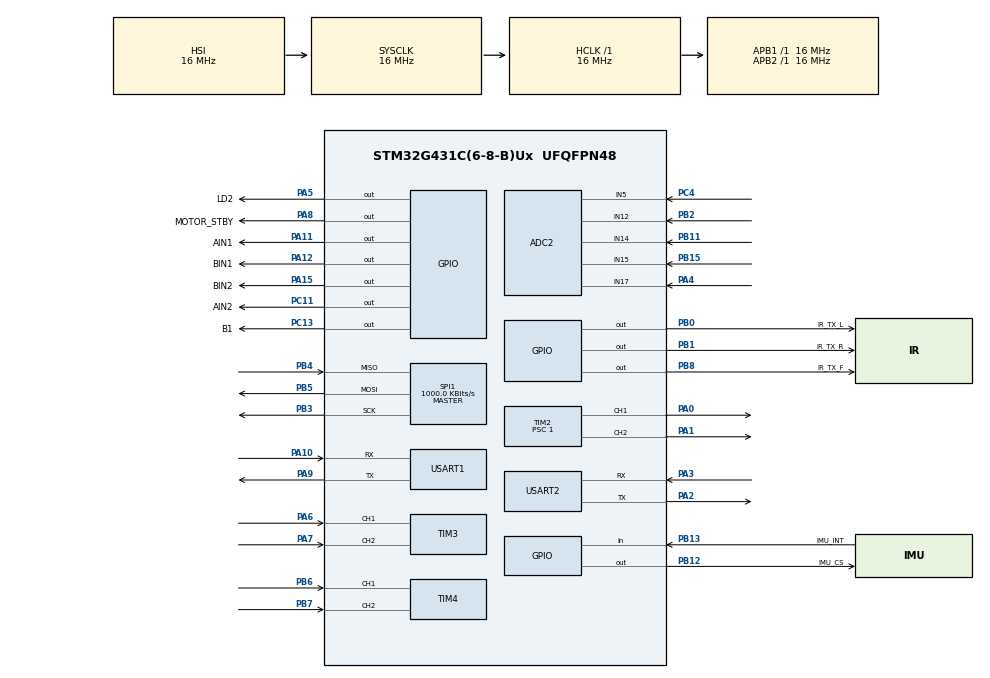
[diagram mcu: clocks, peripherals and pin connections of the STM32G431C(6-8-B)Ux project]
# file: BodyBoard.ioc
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ADC2.Channel-0\#ChannelRegularConversion=ADC_CHANNEL_5
ADC2.ClockPrescaler=ADC_CLOCK_SYNC_PCLK_DIV4
ADC2.NbrOfConversionFlag=1
ADC2.OffsetNumber-0\#ChannelRegularConversion=ADC_OFFSET_NONE
ADC2.Rank-0\#ChannelRegularConversion=1
ADC2.SamplingTime-0\#ChannelRegularConversion=ADC_SAMPLETIME_2CYCLES_5
Dma.Request0=USART1_RX
Dma.Request1=USART1_TX
Dma.USART1_RX.0.Direction=DMA_PERIPH_TO_MEMORY
Dma.USART1_RX.0.EventEnable=DISABLE
Dma.USART1_RX.0.Instance=DMA1_Channel1
Dma.USART1_RX.0.MemDataAlignment=DMA_MDATAALIGN_BYTE
Dma.USART1_RX.0.MemInc=DMA_MINC_ENABLE
Dma.USART1_RX.0.Mode=DMA_CIRCULAR
Dma.USART1_RX.0.PeriphDataAlignment=DMA_PDATAALIGN_BYTE
Dma.USART1_RX.0.PeriphInc=DMA_PINC_DISABLE
Dma.USART1_RX.0.Polarity=HAL_DMAMUX_REQ_GEN_RISING
Dma.USART1_RX.0.Priority=DMA_PRIORITY_LOW
Dma.USART1_RX.0.RequestNumber=1
Dma.USART1_RX.0.SignalID=NONE
Dma.USART1_RX.0.SyncEnable=DISABLE
Dma.USART1_RX.0.SyncPolarity=HAL_DMAMUX_SYNC_NO_EVENT
Dma.USART1_RX.0.SyncRequestNumber=1
Dma.USART1_RX.0.SyncSignalID=NONE
Dma.USART1_TX.1.Direction=DMA_MEMORY_TO_PERIPH
Dma.USART1_TX.1.EventEnable=DISABLE
Dma.USART1_TX.1.Instance=DMA1_Channel2
Dma.USART1_TX.1.MemDataAlignment=DMA_MDATAALIGN_BYTE
Dma.USART1_TX.1.MemInc=DMA_MINC_ENABLE
Dma.USART1_TX.1.Mode=DMA_NORMAL
Dma.USART1_TX.1.PeriphDataAlignment=DMA_PDATAALIGN_BYTE
Dma.USART1_TX.1.PeriphInc=DMA_PINC_DISABLE
Dma.USART1_TX.1.Polarity=HAL_DMAMUX_REQ_GEN_RISING
Dma.USART1_TX.1.Priority=DMA_PRIORITY_LOW
Dma.USART1_TX.1.RequestNumber=1
Dma.USART1_TX.1.SignalID=NONE
Dma.USART1_TX.1.SyncEnable=DISABLE
Dma.USART1_TX.1.SyncPolarity=HAL_DMAMUX_SYNC_NO_EVENT
Dma.USART1_TX.1.SyncRequestNumber=1
Dma.USART1_TX.1.SyncSignalID=NONE
Mcu.Family=STM32G4
Mcu.Name=STM32G431C(6-8-B)Ux
Mcu.Package=UFQFPN48
NVIC.DMA1_Channel1_IRQn=true\:0\:0\:false\:false\:true\:false\:true\:true
NVIC.DMA1_Channel2_IRQn=true\:0\:0\:false\:false\:true\:false\:true\:true
NVIC.PriorityGroup=NVIC_PRIORITYGROUP_4
NVIC.TIM6_DAC_IRQn=true\:0\:0\:false\:false\:true\:true\:true\:true
NVIC.USART1_IRQn=true\:0\:0\:false\:false\:true\:true\:true\:true
PA0.Signal=S_TIM2_CH1
PA1.Signal=S_TIM2_CH2
PA10.Mode=Asynchronous
PA10.Signal=USART1_RX
PA11.GPIO_Label=AIN1
PA11.Signal=GPIO_Output
PA12.GPIO_Label=BIN1
PA12.Signal=GPIO_Output
PA13.Mode=Serial_Wire
PA13.Signal=SYS_JTMS-SWDIO
PA14.Mode=Serial_Wire
PA14.Signal=SYS_JTCK-SWCLK
PA15.GPIO_Label=BIN2
PA15.Signal=GPIO_Output
PA2.Mode=Asynchronous
PA2.Signal=USART2_TX
PA3.Mode=Asynchronous
PA3.Signal=USART2_RX
PA4.Mode=IN17-Single-Ended
PA4.Signal=ADC2_IN17
PA5.GPIO_Label=LD2
PA5.Signal=GPIO_Output
PA6.Signal=S_TIM3_CH1
PA7.Signal=S_TIM3_CH2
PA8.GPIO_Label=MOTOR_STBY
PA8.PinState=GPIO_PIN_RESET
PA8.Signal=GPIO_Output
PA9.Mode=Asynchronous
PA9.Signal=USART1_TX
PB0.GPIO_Label=IR_TX_L
PB0.Signal=GPIO_Output
PB1.GPIO_Label=IR_TX_R
PB1.Signal=GPIO_Output
PB11.Mode=IN14-Single-Ended
PB11.Signal=ADC2_IN14
PB12.GPIO_Label=IMU_CS
PB12.Signal=GPIO_Output
PB13.GPIO_Label=IMU_INT
PB13.Signal=GPIO_Input
PB15.Mode=IN15-Single-Ended
PB15.Signal=ADC2_IN15
PB2.Mode=IN12-Single-Ended
PB2.Signal=ADC2_IN12
PB3.Mode=Full_Duplex_Master
PB3.Signal=SPI1_SCK
PB4.Mode=Full_Duplex_Master
PB4.Signal=SPI1_MISO
PB5.Mode=Full_Duplex_Master
PB5.Signal=SPI1_MOSI
PB6.Signal=S_TIM4_CH1
PB7.Signal=S_TIM4_CH2
PB8-BOOT0.GPIO_Label=IR_TX_F
PB8-BOOT0.Signal=GPIO_Output
PC11.GPIO_Label=AIN2
PC11.Signal=GPIO_Output
PC13.GPIO_Label=B1
PC13.Signal=GPIO_Output
PC4.Mode=IN5-Single-Ended
PC4.Signal=ADC2_IN5
PF0-OSC_IN.Mode=HSE-External-Oscillator
PF0-OSC_IN.Signal=RCC_OSC_IN
PF1-OSC_OUT.Mode=HSE-External-Oscillator
PF1-OSC_OUT.Signal=RCC_OSC_OUT
ProjectManager.HeapSize=0x200
ProjectManager.StackSize=0x400
ProjectManager.TargetToolchain=CMake
RCC.AHBFreq_Value=16000000
RCC.APB1Freq_Value=16000000
RCC.APB1TimFreq_Value=16000000
RCC.APB2Freq_Value=16000000
RCC.APB2TimFreq_Value=16000000
RCC.CortexFreq_Value=16000000
RCC.EXTERNAL_CLOCK_VALUE=12288000
RCC.HCLKFreq_Value=16000000
RCC.HSE_VALUE=8000000
RCC.HSI48_VALUE=48000000
RCC.HSI_VALUE=16000000
RCC.LSE_VALUE=32768
RCC.PLLM=RCC_PLLM_DIV2
RCC.PLLN=85
RCC.PLLSourceVirtual=RCC_PLLSOURCE_HSE
RCC.SYSCLKFreq_VALUE=16000000
RCC.USBFreq_Value=170000000
RCC.VCOOutputFreq_Value=340000000
SH.S_TIM2_CH1.0=TIM2_CH1,PWM Generation1 CH1
SH.S_TIM2_CH2.0=TIM2_CH2,PWM Generation2 CH2
SH.S_TIM3_CH1.0=TIM3_CH1,Encoder_Interface
SH.S_TIM3_CH2.0=TIM3_CH2,Encoder_Interface
SH.S_TIM4_CH1.0=TIM4_CH1,Encoder_Interface
SH.S_TIM4_CH2.0=TIM4_CH2,Encoder_Interface
SPI1.BaudRatePrescaler=SPI_BAUDRATEPRESCALER_16
SPI1.CLKPhase=SPI_PHASE_2EDGE
SPI1.CLKPolarity=SPI_POLARITY_HIGH
SPI1.CalculateBaudRate=1000.0 KBits/s
SPI1.DataSize=SPI_DATASIZE_8BIT
SPI1.Direction=SPI_DIRECTION_2LINES
SPI1.Mode=SPI_MODE_MASTER
SPI1.VirtualType=VM_MASTER
TIM2.Channel-PWM\ Generation1\ CH1=TIM_CHANNEL_1
TIM2.Channel-PWM\ Generation2\ CH2=TIM_CHANNEL_2
TIM2.PeriodNoDither=4199
TIM2.Prescaler=1
TIM3.EncoderMode=TIM_ENCODERMODE_TI12
TIM3.IC1Filter=8
TIM4.EncoderMode=TIM_ENCODERMODE_TI12
TIM4.IC1Filter=8
TIM6.PeriodNoDither=999
TIM6.Prescaler=169
USART1.VirtualMode-Asynchronous=VM_ASYNC
USART2.VirtualMode-Asynchronous=VM_ASYNC
VP_SYS_VS_DBSignals.Mode=DisableDeadBatterySignals
VP_TIM2_VS_ClockSourceINT.Mode=Internal
VP_TIM6_VS_ClockSourceINT.Mode=Enable_Timer
board=custom

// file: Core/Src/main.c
/* USER CODE BEGIN Header */
/**
  ******************************************************************************
  * @file           : main.c
  * @brief          : Main program body
  ******************************************************************************
  * @attention
  *
  * Copyright (c) 2026 STMicroelectronics.
  * All rights reserved.
  *
  * This software is licensed under terms that can be found in the LICENSE file
  * in the root directory of this software component.
  * If no LICENSE file comes with this software, it is provided AS-IS.
  *
  ******************************************************************************
  */
/* USER CODE END Header */
#include "main.h"
#include "adc.h"
#include "dma.h"
#include "spi.h"
#include "tim.h"
#include "usart.h"
#include "gpio.h"

/* USER CODE BEGIN Includes */
#include "app_main.h"
/* USER CODE END Includes */

void SystemClock_Config(void);

int main(void)
{

  /* MCU Configuration--------------------------------------------------------*/

  /* Reset of all peripherals, Initializes the Flash interface and the Systick. */
  HAL_Init();

  /* Configure the system clock */
  SystemClock_Config();

  /* Initialize all configured peripherals */
  MX_GPIO_Init();
  MX_DMA_Init();
  MX_ADC2_Init();
  MX_SPI1_Init();
  MX_TIM2_Init();
  MX_TIM3_Init();
  MX_TIM6_Init();
  MX_USART1_UART_Init();
  MX_USART2_UART_Init();
  MX_TIM4_Init();
  /* USER CODE BEGIN 2 */
  app_setup();
  /* USER CODE END 2 */

  /* Infinite loop */
  while (1)
  {

    /* USER CODE BEGIN 3 */
    app_loop();
  }
  /* USER CODE END 3 */
}

void SystemClock_Config(void)
{
  RCC_OscInitTypeDef RCC_OscInitStruct = {0};
  RCC_ClkInitTypeDef RCC_ClkInitStruct = {0};

  /** Configure the main internal regulator output voltage
  */
  HAL_PWREx_ControlVoltageScaling(PWR_REGULATOR_VOLTAGE_SCALE1);

  /** Initializes the RCC Oscillators according to the specified parameters
  * in the RCC_OscInitTypeDef structure.
  */
  RCC_OscInitStruct.OscillatorType = RCC_OSCILLATORTYPE_HSI;
  RCC_OscInitStruct.HSIState = RCC_HSI_ON;
  RCC_OscInitStruct.HSICalibrationValue = RCC_HSICALIBRATION_DEFAULT;
  RCC_OscInitStruct.PLL.PLLState = RCC_PLL_NONE;
  if (HAL_RCC_OscConfig(&RCC_OscInitStruct) != HAL_OK)
  {
    Error_Handler();
  }

  /** Initializes the CPU, AHB and APB buses clocks
  */
  RCC_ClkInitStruct.ClockType = RCC_CLOCKTYPE_HCLK|RCC_CLOCKTYPE_SYSCLK
                              |RCC_CLOCKTYPE_PCLK1|RCC_CLOCKTYPE_PCLK2;
  RCC_ClkInitStruct.SYSCLKSource = RCC_SYSCLKSOURCE_HSI;
  RCC_ClkInitStruct.AHBCLKDivider = RCC_SYSCLK_DIV1;
  RCC_ClkInitStruct.APB1CLKDivider = RCC_HCLK_DIV1;
  RCC_ClkInitStruct.APB2CLKDivider = RCC_HCLK_DIV1;

  if (HAL_RCC_ClockConfig(&RCC_ClkInitStruct, FLASH_LATENCY_0) != HAL_OK)
  {
    Error_Handler();
  }
}

void Error_Handler(void)
{
  __disable_irq();
  while (1)
  {
  }
}
